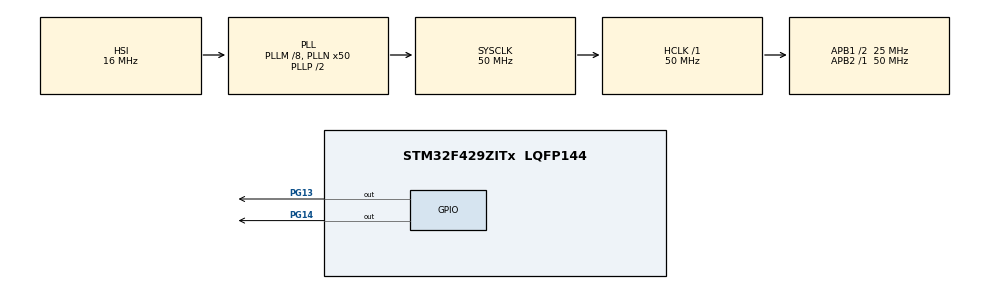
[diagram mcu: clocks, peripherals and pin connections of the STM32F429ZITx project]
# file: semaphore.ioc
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FREERTOS.BinarySemaphores01=myBinarySem01,Dynamic,NULL,Available
FREERTOS.Tasks01=led_on,24,128,Startledon,Default,NULL,Dynamic,NULL,NULL;ledoff,8,128,Startledoff,Default,NULL,Dynamic,NULL,NULL
FREERTOS.configUSE_NEWLIB_REENTRANT=1
Mcu.Family=STM32F4
Mcu.Name=STM32F429ZITx
Mcu.Package=LQFP144
NVIC.PriorityGroup=NVIC_PRIORITYGROUP_4
NVIC.TIM1_UP_TIM10_IRQn=true\:15\:0\:false\:false\:true\:false\:false\:true\:true
NVIC.TimeBase=TIM1_UP_TIM10_IRQn
NVIC.TimeBaseIP=TIM1
PG13.Signal=GPIO_Output
PG14.Signal=GPIO_Output
PH0/OSC_IN.Mode=HSE-External-Oscillator
PH0/OSC_IN.Signal=RCC_OSC_IN
PH1/OSC_OUT.Mode=HSE-External-Oscillator
PH1/OSC_OUT.Signal=RCC_OSC_OUT
ProjectManager.HeapSize=0x200
ProjectManager.StackSize=0x400
ProjectManager.TargetToolchain=STM32CubeIDE
RCC.48MHZClocksFreq_Value=25000000
RCC.AHBFreq_Value=50000000
RCC.APB1CLKDivider=RCC_HCLK_DIV2
RCC.APB1Freq_Value=25000000
RCC.APB1TimFreq_Value=50000000
RCC.APB2Freq_Value=50000000
RCC.APB2TimFreq_Value=50000000
RCC.CortexFreq_Value=50000000
RCC.HCLKFreq_Value=50000000
RCC.HSE_VALUE=25000000
RCC.HSI_VALUE=16000000
RCC.LSE_VALUE=32768
RCC.PLLM=8
RCC.PLLN=50
RCC.SYSCLKFreq_VALUE=50000000
RCC.SYSCLKSource=RCC_SYSCLKSOURCE_PLLCLK
RCC.VCOOutputFreq_Value=100000000
VP_FREERTOS_VS_CMSIS_V2.Mode=CMSIS_V2
VP_SYS_VS_tim1.Mode=TIM1
board=custom

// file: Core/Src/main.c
/* USER CODE BEGIN Header */
/**
  ******************************************************************************
  * @file           : main.c
  * @brief          : Main program body
  ******************************************************************************
  * @attention
  *
  * Copyright (c) 2025 STMicroelectronics.
  * All rights reserved.
  *
  * This software is licensed under terms that can be found in the LICENSE file
  * in the root directory of this software component.
  * If no LICENSE file comes with this software, it is provided AS-IS.
  *
  ******************************************************************************
  */
/* USER CODE END Header */
#include "main.h"
#include "cmsis_os.h"

/* Definitions for led_on */
osThreadId_t led_onHandle;
const osThreadAttr_t led_on_attributes = {
  .name = "led_on",
  .stack_size = 128 * 4,
  .priority = (osPriority_t) osPriorityNormal,
};
/* Definitions for ledoff */
osThreadId_t ledoffHandle;
const osThreadAttr_t ledoff_attributes = {
  .name = "ledoff",
  .stack_size = 128 * 4,
  .priority = (osPriority_t) osPriorityLow,
};
/* Definitions for myBinarySem01 */
osSemaphoreId_t myBinarySem01Handle;
const osSemaphoreAttr_t myBinarySem01_attributes = {
  .name = "myBinarySem01"
};

void SystemClock_Config(void);
static void MX_GPIO_Init(void);
void Startledon(void *argument);
void Startledoff(void *argument);

int main(void)
{

  /* MCU Configuration--------------------------------------------------------*/

  /* Reset of all peripherals, Initializes the Flash interface and the Systick. */
  HAL_Init();

  /* Configure the system clock */
  SystemClock_Config();

  /* USER CODE BEGIN SysInit */
//  xSemaphore = xSemaphoreCreateBinary();
  /* USER CODE END SysInit */

  /* Initialize all configured peripherals */
  MX_GPIO_Init();

  /* Init scheduler */
  osKernelInitialize();

  /* Create the semaphores(s) */
  /* creation of myBinarySem01 */
  myBinarySem01Handle = osSemaphoreNew(1, 1, &myBinarySem01_attributes);

  /* Create the thread(s) */
  /* creation of led_on */
  led_onHandle = osThreadNew(Startledon, NULL, &led_on_attributes);

  /* creation of ledoff */
  ledoffHandle = osThreadNew(Startledoff, NULL, &ledoff_attributes);

  /* Start scheduler */
  osKernelStart();

  /* We should never get here as control is now taken by the scheduler */

  /* Infinite loop */
  while (1)
  {

  }
}

void SystemClock_Config(void)
{
  RCC_OscInitTypeDef RCC_OscInitStruct = {0};
  RCC_ClkInitTypeDef RCC_ClkInitStruct = {0};

  /** Configure the main internal regulator output voltage
  */
  __HAL_RCC_PWR_CLK_ENABLE();
  __HAL_PWR_VOLTAGESCALING_CONFIG(PWR_REGULATOR_VOLTAGE_SCALE3);

  /** Initializes the RCC Oscillators according to the specified parameters
  * in the RCC_OscInitTypeDef structure.
  */
  RCC_OscInitStruct.OscillatorType = RCC_OSCILLATORTYPE_HSI;
  RCC_OscInitStruct.HSIState = RCC_HSI_ON;
  RCC_OscInitStruct.HSICalibrationValue = RCC_HSICALIBRATION_DEFAULT;
  RCC_OscInitStruct.PLL.PLLState = RCC_PLL_ON;
  RCC_OscInitStruct.PLL.PLLSource = RCC_PLLSOURCE_HSI;
  RCC_OscInitStruct.PLL.PLLM = 8;
  RCC_OscInitStruct.PLL.PLLN = 50;
  RCC_OscInitStruct.PLL.PLLP = RCC_PLLP_DIV2;
  RCC_OscInitStruct.PLL.PLLQ = 4;
  if (HAL_RCC_OscConfig(&RCC_OscInitStruct) != HAL_OK)
  {
    Error_Handler();
  }

  /** Initializes the CPU, AHB and APB buses clocks
  */
  RCC_ClkInitStruct.ClockType = RCC_CLOCKTYPE_HCLK|RCC_CLOCKTYPE_SYSCLK
                              |RCC_CLOCKTYPE_PCLK1|RCC_CLOCKTYPE_PCLK2;
  RCC_ClkInitStruct.SYSCLKSource = RCC_SYSCLKSOURCE_PLLCLK;
  RCC_ClkInitStruct.AHBCLKDivider = RCC_SYSCLK_DIV1;
  RCC_ClkInitStruct.APB1CLKDivider = RCC_HCLK_DIV2;
  RCC_ClkInitStruct.APB2CLKDivider = RCC_HCLK_DIV1;

  if (HAL_RCC_ClockConfig(&RCC_ClkInitStruct, FLASH_LATENCY_1) != HAL_OK)
  {
    Error_Handler();
  }
}

static void MX_GPIO_Init(void)
{
  GPIO_InitTypeDef GPIO_InitStruct = {0};

  /* GPIO Ports Clock Enable */
  __HAL_RCC_GPIOH_CLK_ENABLE();
  __HAL_RCC_GPIOG_CLK_ENABLE();

  /*Configure GPIO pin Output Level */
  HAL_GPIO_WritePin(GPIOG, GPIO_PIN_13|GPIO_PIN_14, GPIO_PIN_RESET);

  /*Configure GPIO pins : PG13 PG14 */
  GPIO_InitStruct.Pin = GPIO_PIN_13|GPIO_PIN_14;
  GPIO_InitStruct.Mode = GPIO_MODE_OUTPUT_PP;
  GPIO_InitStruct.Pull = GPIO_NOPULL;
  GPIO_InitStruct.Speed = GPIO_SPEED_FREQ_LOW;
  HAL_GPIO_Init(GPIOG, &GPIO_InitStruct);

}

void Startledon(void *argument)
{
  /* USER CODE BEGIN 5 */
  /* Infinite loop */
	osSemaphoreRelease(myBinarySem01Handle);
  for(;;)
  {

	  if (osSemaphoreAcquire(myBinarySem01Handle, osWaitForever) == osOK) {
	              HAL_GPIO_WritePin(GPIOG, GPIO_PIN_13, GPIO_PIN_SET);
	              osDelay(1000);
	              osSemaphoreRelease(myBinarySem01Handle);
  }
  /* USER CODE END 5 */
	  osDelay(1000);
}
}

void Startledoff(void *argument)
{
  /* USER CODE BEGIN Startledoff */
  /* Infinite loop */
	osSemaphoreRelease(myBinarySem01Handle);
  for(;;)
  {
	  if (osSemaphoreAcquire(myBinarySem01Handle, osWaitForever) == osOK) {
	             HAL_GPIO_WritePin(GPIOG, GPIO_PIN_13, GPIO_PIN_RESET);
	             osDelay(1000);
	             osSemaphoreRelease(myBinarySem01Handle);

  /* USER CODE END Startledoff */
}
	  osDelay(1000);
}
}

void HAL_TIM_PeriodElapsedCallback(TIM_HandleTypeDef *htim)
{
  if (htim->Instance == TIM1) {
    HAL_IncTick();
  }
}

void Error_Handler(void)
{
  __disable_irq();
  while (1)
  {
  }
}
